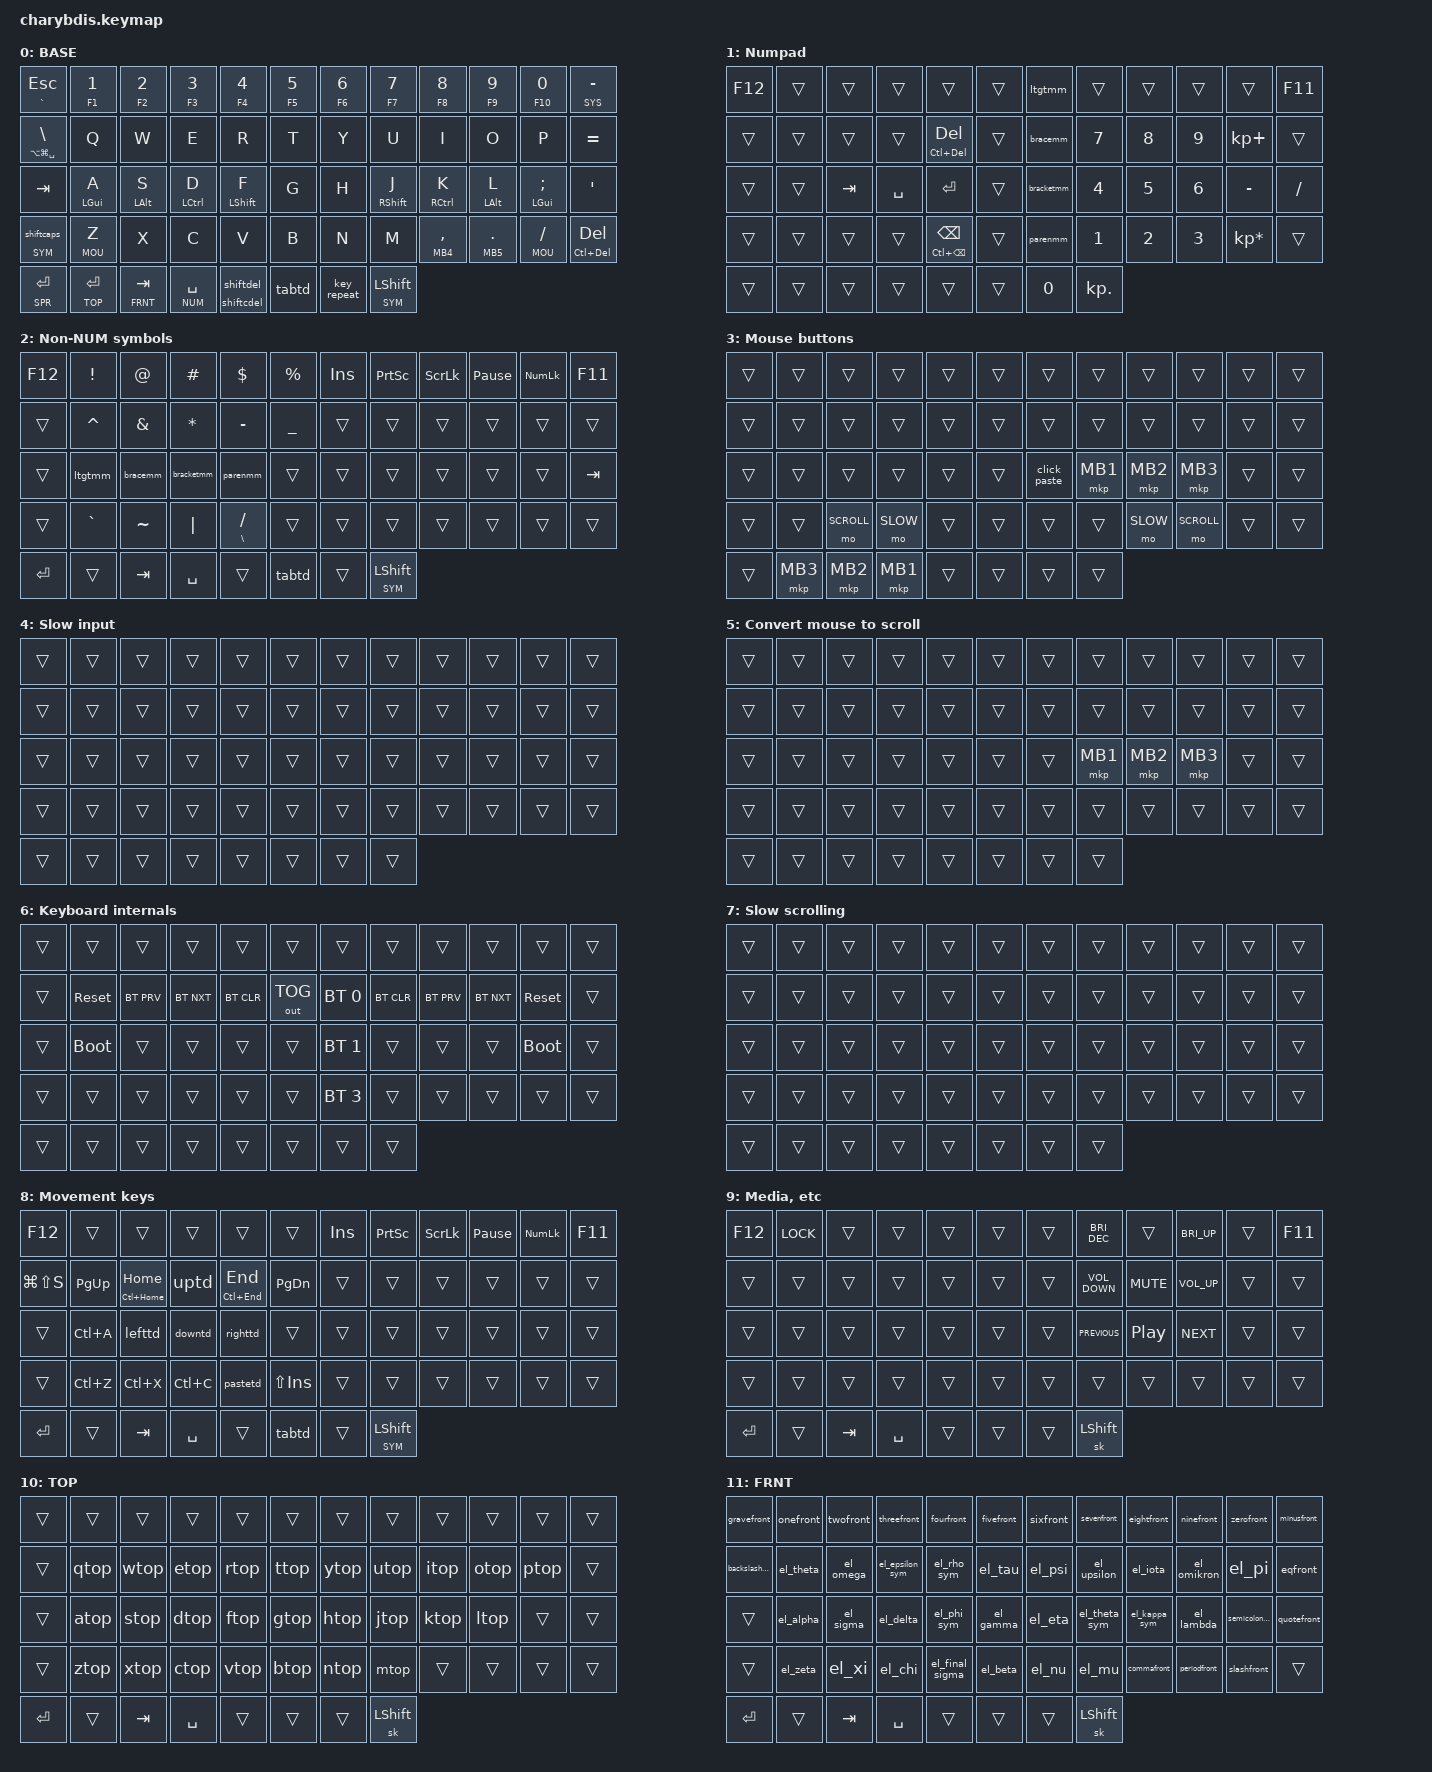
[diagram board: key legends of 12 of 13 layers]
// dt-formatter: indent="  "
#include <dt-bindings/zmk/mouse.h>
#include <behaviors/mouse_keys.dtsi>
#include <input/processors.dtsi>
#include <dt-bindings/zmk/input_transform.h>
#include <behaviors/mouse_move.dtsi>

#include <behaviors.dtsi>
#include <dt-bindings/zmk/bt.h>
#include <dt-bindings/zmk/keys.h>
#include <dt-bindings/zmk/outputs.h>
#include <dt-bindings/zmk/pointing.h>

// Can't move these into tree? Get moved by Keymap-Editor, annoyingly.
#include "zmk-helpers/helper.h" // Source after behaviors.dtsi
#include "zmk-helpers/unicode-chars/greek.dtsi" // Named Greek language characters for Front layer
#include "unicode.dtsi" // Single unicode chars for Top layer

// Utility
#define __ &trans
#define BASE 0
#define NUM 1
#define SYM 2
#define MOU 3
#define SLOW 4
#define SCROLL 5
#define SYS 6
#define SLSC 7
#define NAV 8
#define SPR 9
#define TOP 10
#define FRNT 11
#define WIN 12

// Set default row/column to actual key grid transform
/ {
  chosen { zmk,matrix_transform = &default_transform; };
};

// Default mod-tap settings
&mt {
  quick-tap-ms = <100>;
  global-quick-tap;
  flavor = "tap-preferred";
  tapping-term-ms = <170>;
};

// Default layer-tap settings
&lt {
  quick-tap-ms = <100>;
  global-quick-tap;
  flavor = "tap-preferred";
  tapping-term-ms = <170>;
};

// Defaults for caps-word behaviour
&caps_word { continue-list = <UNDERSCORE BACKSPACE DELETE MINUS>; };

// zip scaler takes mult/divisor to create multiplier. 1.5x is too fast. 1 seems fine?
&trackball_listener {
  input-processors =
    <&zip_xy_transform (INPUT_TRANSFORM_Y_INVERT | INPUT_TRANSFORM_X_INVERT | INPUT_TRANSFORM_XY_SWAP)>,
    <&zip_xy_scaler 5 4>,
    <&my_temp_layer MOU 500>;

  sniper {
    layers = <SLOW SLSC>;
    input-processors = <&zip_xy_scaler 1 8>;
    process-next;
  };

  scroller {
    layers = <SCROLL SLSC>;
    input-processors =
      <&zip_xy_transform (INPUT_TRANSFORM_X_INVERT | INPUT_TRANSFORM_XY_SWAP)>,
      <&zip_xy_to_scroll_mapper>;
  };
};

/ {
  combos {
		compatible = "zmk,combos";

		winmove {
      bindings = <&mo WIN>;
      key-positions = <55 53>;
    };
	};

  macros {
    click_paste: click_paste {
      compatible = "zmk,behavior-macro";
      #binding-cells = <0>;
      bindings
        = <&macro_tap &mkp MB1>
        , <&kp LC(V)>
        ;
    };
  };

  behaviors {
		/* Fancy alt-tab on single key. Might remove timeout to get used to interrup
			 ting with a key */
    swapper: swapper {
      compatible = "zmk,behavior-tri-state";
      #binding-cells = <0>;
      timeout-ms = <1500>; // Fire behavior x ms after release, *or* when a non-ignored key is pressed
      ignored-key-positions = <24 27 31 55 53>;

      bindings = <&kt LALT>, <&kp TAB>, <&kt LALT>;
    };

		/* Mouse buttons on hold for forward/back */
    mouse_tap: mouse_tap {
      compatible = "zmk,behavior-hold-tap";
      bindings = <&mkp>, <&kp>;

      #binding-cells = <2>;
      flavor = "tap-preferred";
      tapping-term-ms = <170>;
      quick-tap-ms = <100>;
    };

		/* Adds layer on hold to existing caps word/caps lock behaviour */
    caps_tap: caps_tap {
      compatible = "zmk,behavior-hold-tap";
      bindings = <&mo>, <&shiftcaps>;

      #binding-cells = <2>;
      tapping-term-ms = <170>;
      quick-tap-ms = <100>;
      flavor = "tap-preferred";
    };

		/* Hold-tap for backspace and delete */
		backspace_tap: backspace_tap {
      compatible = "zmk,behavior-hold-tap";
      bindings = <&shiftcdel>, <&shiftdel>;

      #binding-cells = <2>;
      tapping-term-ms = <170>;
      quick-tap-ms = <100>;
      flavor = "tap-preferred";
    };

		/* Home Row Mod behaviours */
    rhtap: rhtap {
      compatible = "zmk,behavior-hold-tap";
      bindings = <&kp>, <&kp>;

      #binding-cells = <2>;
      tapping-term-ms = <300>;
      quick-tap-ms = <175>;
			require-prior-idle-ms = <25>;
      flavor = "balanced";
      hold-trigger-key-positions = <13 25 14 26 37 38 39 15 27 16 40 28 17 29 41 5 4 3 2 1 0 24 49 52 51 12 36 50 48>;
      hold-trigger-on-release;
    };

		rhshift: rhshift {
      compatible = "zmk,behavior-hold-tap";
      bindings = <&kp>, <&kp>;

      #binding-cells = <2>;
      tapping-term-ms = <300>;
      quick-tap-ms = <175>;
			// require-prior-idle-ms = <25>; // Remove this for shift key only?
      flavor = "balanced";
      hold-trigger-key-positions = <13 25 14 26 37 38 39 15 27 16 40 28 17 29 41 5 4 3 2 1 0 24 49 52 51 12 36 50 48>;
      hold-trigger-on-release;
    };

    lhtap: lhtap {
      compatible = "zmk,behavior-hold-tap";
      bindings = <&kp>, <&kp>;

      #binding-cells = <2>;
      tapping-term-ms = <300>;
      quick-tap-ms = <175>;
			require-prior-idle-ms = <25>;
      flavor = "balanced";
      hold-trigger-key-positions = <18 22 30 31 32 33 34 42 43 44 45 46 19 20 21 22 54 10 9 8 7 6 10 11 22 23 35 47 55 53>;
      hold-trigger-on-release;
    };

		lhshift: lhshift {
      compatible = "zmk,behavior-hold-tap";
      bindings = <&kp>, <&kp>;

      #binding-cells = <2>;
      tapping-term-ms = <300>;
      quick-tap-ms = <175>;
			// require-prior-idle-ms = <25>; // Remove this for shift key only? 
      flavor = "balanced";
      hold-trigger-key-positions = <18 22 30 31 32 33 34 42 43 44 45 46 19 20 21 22 54 10 9 8 7 6 10 11 22 23 35 47 55 53>;
      hold-trigger-on-release;
    };

		/* Arrow keys - still a work in progress */
    lefttd: lefttd {
      compatible = "zmk,behavior-tap-dance";
      #binding-cells = <0>;
      bindings = <&kp LEFT_ARROW>, <&mt LC(LS(LEFT_ARROW)) LC(LEFT_ARROW)>;
    };

    righttd: righttd {
      compatible = "zmk,behavior-tap-dance";
      #binding-cells = <0>;
      bindings = <&mt LC(LS(RIGHT_ARROW)) RIGHT_ARROW>, <&kp LC(RIGHT_ARROW)>;
    };

    uptd: uptd {
      compatible = "zmk,behavior-tap-dance";
      #binding-cells = <0>;
      bindings = <&mt LC(LS(UP_ARROW)) UP_ARROW>, <&kp LC(UP_ARROW)>;
    };

    downtd: downtd {
      compatible = "zmk,behavior-tap-dance";
      #binding-cells = <0>;
      bindings = <&mt LC(LS(DOWN_ARROW)) DOWN_ARROW>, <&kp LC(DOWN_ARROW)>;
    };

		/* For nav layer; paste on single tap, windows paste on 2 taps */
    pastetd: pastetd {
      compatible = "zmk,behavior-tap-dance";
      #binding-cells = <0>;
      bindings = <&kp LC(V)>, <&kp LG(V)>;
    };

    /* Left bracket on normal press, right bracket on shift-press */
    bracketmm: bracketmm {
      compatible = "zmk,behavior-mod-morph";
      bindings = <&kp LEFT_BRACKET>, <&kp RIGHT_BRACKET>;

      #binding-cells = <0>;
      mods = <(MOD_RSFT|MOD_LSFT)>;
    };

    parenmm: parenmm {
      compatible = "zmk,behavior-mod-morph";
      bindings = <&kp LEFT_PARENTHESIS>, <&kp RIGHT_PARENTHESIS>;

      #binding-cells = <0>;
      mods = <(MOD_LSFT|MOD_RSFT)>;
    };

    bracemm: bracemm {
      compatible = "zmk,behavior-mod-morph";
      bindings = <&kp LEFT_BRACE>, <&kp RIGHT_BRACE>;

      #binding-cells = <0>;
      mods = <(MOD_LSFT|MOD_RSFT)>;
    };

    ltgtmm: ltgtmm {
      compatible = "zmk,behavior-mod-morph";
      bindings = <&kp LESS_THAN>, <&kp GREATER_THAN>;

      #binding-cells = <0>;
      mods = <(MOD_LSFT|MOD_RSFT)>;
    };

		/* Sticky shift + Layer on hold */
    stickyshift_tap: stickyshift_tap {
      compatible = "zmk,behavior-hold-tap";
      bindings = <&mo>, <&sk>;

      #binding-cells = <2>;
      tapping-term-ms = <170>;
      quick-tap-ms = <100>;
      flavor = "tap-preferred";
    };
		
		/* Existing caps word behaviour on tap + Real caps lock on Shift-tap. Can be
			 combined into a further mod-tap for layers.  */
    shiftcaps: shiftcaps {
      compatible = "zmk,behavior-mod-morph";
      bindings = <&caps_word>, <&kp CAPSLOCK>;

      #binding-cells = <0>;
      mods = <(MOD_LSFT|MOD_RSFT)>;
    };

    /* Backspace normally, delete on shift */
		shiftdel: shiftdel {
      compatible = "zmk,behavior-mod-morph";
      bindings = <&kp BACKSPACE>, <&kp DELETE>;

      #binding-cells = <0>;
      mods = <(MOD_LSFT|MOD_RSFT)>;
    };

    /* C-Backspace normally, C-delete on shift */
		shiftcdel: shiftcdel {
      compatible = "zmk,behavior-mod-morph";
      bindings = <&kp LC(BACKSPACE)>, <&kp LC(DELETE)>;

      #binding-cells = <0>;
      mods = <(MOD_LSFT|MOD_RSFT)>;
    };
		
		/* Runs swapper on hold of tab key */
    tabtap: tabtap {
      compatible = "zmk,behavior-hold-tap";
      bindings = <&swapper>, <&kp>;

      #binding-cells = <2>;
      tapping-term-ms = <170>;
      flavor = "tap-preferred";
    };

    /* Run swapper on double-tap of layer key, alt tab on single tap */
		tabtd: tabtd {
			compatible = "zmk,behavior-tap-dance";
			#binding-cells = <0>;
			bindings = <&lt NAV LA(TAB)>, <&swapper>;
 		};

		/* layertab: layertab { */
		/* 	compatible = "zmk,behavior-hold-tap"; */
		/* 	bindings = <&mo>, <&tabtd>; */
		/* 	#binding-cells = <2>; */
		/* 	tapping-term-ms = <170>; */
		/* 	flavor = "tap-preferred"; */
		/* }; */

    /* Zip-to-layer for mouse mode */
    /omit-if-no-ref/
    my_temp_layer: my_temp_layer {
      compatible = "zmk,input-processor-temp-layer";
      #input-processor-cells = <2>;
      require-prior-idle-ms = <500>;
      excluded-positions = <31 32 33 37 38 39 44 45 46>;
    };
  };

  keymap {
    compatible = "zmk,keymap";

    BASE {
      bindings = <
      // 0-11
      &mt GRAVE ESCAPE  &mt F1 NUMBER_1  &mt F2 NUMBER_2  &mt F3 NUMBER_3  &mt F4 NUMBER_4  &mt F5 NUMBER_5  &mt F6 NUMBER_6  &mt F7 NUMBER_7  &mt F8 NUMBER_8  &mt F9 NUMBER_9  &mt F10 NUMBER_0  &lt SYS MINUS
      // 12-23
      &mt LA(LG(SPACE)) BACKSLASH  &kp Q  &kp W  &kp E  &kp R  &kp T  &kp Y  &kp U  &kp I  &kp O  &kp P  &kp EQUAL
      // 24-35
      &kp TAB  &lhtap LEFT_GUI A  &lhtap LALT S  &lhtap LCTRL D  &lhshift LSHIFT F  &kp G  &kp H  &rhshift RSHIFT J  &rhtap RCTRL K  &rhtap LEFT_ALT L  &rhtap LEFT_GUI SEMI  &kp APOS
      // 36-47
      &caps_tap SYM 0  &lt MOU Z  &kp X  &kp C  &kp V  &kp B  &kp N  &kp M  &mouse_tap MB4 COMMA  &mouse_tap MB5 PERIOD  &lt MOU SLASH  &mt LC(DELETE) DELETE
      // 48-55; Physical left hand: 50, 51, 48, 52, 49; Right hand: 55, 54, 53
      &lt SPR ENTER  &lt TOP ENTER  &lt FRNT TAB  &lt NUM SPACE  &backspace_tap 0 0  &tabtd  &key_repeat  &stickyshift_tap SYM LEFT_SHIFT
      >;
    };

    NUM {
      bindings = <
      &kp F12    __  __       __         __                           __  &ltgtmm     __      __      __      __               &kp F11
      __         __  __       __         &mt LC(DEL) DELETE           __  &bracemm    &kp N7  &kp N8  &kp N9  &kp KP_PLUS      __
      __         __  &kp TAB  &kp SPACE  &kp ENTER                    __  &bracketmm  &kp N4  &kp N5  &kp N6  &kp MINUS        &kp SLASH
      __         __  __       __         &mt LC(BACKSPACE) BACKSPACE  __  &parenmm    &kp N1  &kp N2  &kp N3  &kp KP_MULTIPLY  __
      __         __  __       __         __                           __  &kp N0      &kp KP_DOT
      >;

      display-name = "Numpad";
    };

    /* Note - haven't had much use for symbol layer; just use number keys. */
    SYM {
      bindings = <
&kp F12  &kp EXCLAMATION  &kp AT_SIGN    &kp HASH      &kp DOLLAR           &kp PERCENT  &kp INSERT          &kp PRINTSCREEN  &kp SCROLLLOCK  &kp PAUSE_BREAK  &kp KP_NUMLOCK  &kp F11
__   &kp CARET        &kp AMPERSAND  &kp ASTERISK  &kp MINUS            &kp UNDER                __  __           __          __           __          __
__   &ltgtmm          &bracemm       &bracketmm    &parenmm             __                   __  __           __          __           __          &kp TAB
__   &kp GRAVE        &kp TILDE      &kp PIPE      &mt BACKSLASH SLASH  __                   __  __           __          __           __          __
         &kp ENTER        __         &kp TAB       &kp SPACE            __       &tabtd              __                           &stickyshift_tap SYM LEFT_SHIFT
      >;

      display-name = "Non-NUM symbols";
    };

    MOU {
      bindings = <
__  __  __    __    __    __  __          __    __    __    __  __
__  __  __    __    __    __          __  __    __    __    __  __
__  __  __    __    __    __         &click_paste  &mkp MB1  &mkp MB2  &mkp MB3  __  __
__  __  &mo SCROLL     &mo SLOW     __    __          __  __    &mo SLOW     &mo SCROLL     __  __
        __  &mkp MB3  &mkp MB2  &mkp MB1  __  __          __              __
      >;

      display-name = "Mouse buttons";
    };

    SLOW {
      bindings = <
      __  __  __  __  __  __  __          __  __  __  __  __
      __  __  __  __  __  __          __  __  __  __  __  __
      __  __  __  __  __  __          __  __  __  __  __  __
      __  __  __  __  __  __          __  __  __  __  __  __
      __  __  __  __  __  __          __          __
      >;

      display-name = "Slow input";
    };

    SCROLL {
      bindings = <
      __  __  __  __  __  __  __          __    __    __    __  __
      __  __  __  __  __  __          __  __    __    __    __  __
      __  __  __  __  __  __          __  &mkp MB1  &mkp MB2  &mkp MB3  __  __
      __  __  __  __  __  __          __  __    __    __    __  __
      __  __  __  __  __  __          __              __
      >;

      display-name = "Convert mouse to scroll";
    };

    SYS {
      bindings = <
      __  __       __      __      __      __        __                __      __      __      __       __
      __  &sys_reset   &bt BT_PRV  &bt BT_NXT  &bt BT_CLR  &out OUT_TOG          &bt BT_SEL 0  &bt BT_CLR  &bt BT_PRV  &bt BT_NXT  &sys_reset   __
      __  &bootloader  __      __      __      __                &bt BT_SEL 1  __      __      __      &bootloader  __
      __  __       __      __      __      __                &bt BT_SEL 3  __      __      __      __       __
      __  __  __  __  __  __  __  __
      >;

      display-name = "Keyboard internals";
    };

    SLSC {
      bindings = <
      __  __  __  __  __  __  __  __  __  __  __  __
      __  __  __  __  __  __  __  __  __  __  __  __
      __  __  __  __  __  __  __  __  __  __  __  __
      __  __  __  __  __  __  __  __  __  __  __  __
      __  __  __  __  __  __  __  __
      >;

      display-name = "Slow scrolling";
    };

    NAV {
      bindings = <
      &kp F12                  __       __             __     __           __         &kp INS          &kp PRINTSCREEN  &kp SCROLLLOCK  &kp PAUSE_BREAK  &kp KP_NUMLOCK  &kp F11
      &kp LG(LS(S))  &kp PAGE_UP  &mt LC(HOME) HOME  &uptd      &mt LC(END) END  &kp PAGE_DOWN           __  __           __          __           __          __
      __                   &kp LC(A)    &lefttd            &downtd    &righttd         __                  __  __           __          __           __          __
      __                   &kp LC(Z)    &kp LC(X)          &kp LC(C)  &pastetd         &kp LS(INS)             __  __           __          __           __          __
      &kp ENTER  __  &kp TAB  &kp SPACE  __  &tabtd  __  &stickyshift_tap SYM LEFT_SHIFT
      >;

      display-name = "Movement keys";
    };

    SPR {
      bindings = <
&kp F12  &kp K_LOCK  __  __   __     __  __          &kp C_BRIGHTNESS_DEC  __            &kp C_BRI_UP     __  &kp F11
__   __      __  __   __     __          __  &kp C_VOLUME_DOWN     &kp C_MUTE        &kp C_VOLUME_UP  __  __
__   __      __  __   __     __          __  &kp C_PREVIOUS        &kp C_PLAY_PAUSE  &kp C_NEXT       __  __
__   __      __  __   __     __          __  __                __            __           __  __
         &kp ENTER   __  &kp TAB  &kp SPACE  __  __          __                                  &sk LEFT_SHIFT
      >;

      display-name = "Media, etc";
    };

    TOP {
      bindings = <
__  __     __  __   __     __  __         __  __  __      __  __
__  &qtop      &wtop   &etop    &rtop      &ttop           &ytop  &utop   &itop   &otop       &ptop   __
__  &atop      &stop   &dtop    &ftop      &gtop           &htop  &jtop   &ktop   &ltop       __  __
__  &ztop      &xtop   &ctop    &vtop      &btop           &ntop  &mtop   __  __      __  __
        &kp ENTER  __  &kp TAB  &kp SPACE  __  __         __          &sk LSHIFT
      >;
    };

    FRNT {
      bindings = <
&gravefront      &onefront  &twofront  &threefront      &fourfront       &fivefront  &sixfront           &sevenfront    &eightfront    &ninefront      &zerofront       &minusfront
&backslashfront  &el_theta  &el_omega  &el_epsilon_sym  &el_rho_sym      &el_tau                &el_psi  &el_upsilon    &el_iota       &el_omikron     &el_pi           &eqfront
__           &el_alpha  &el_sigma  &el_delta        &el_phi_sym      &el_gamma              &el_eta  &el_theta_sym  &el_kappa_sym  &el_lambda      &semicolonfront  &quotefront
__           &el_zeta   &el_xi     &el_chi          &el_final_sigma  &el_beta               &el_nu   &el_mu         &commafront    &periodfront    &slashfront      __
                 &kp ENTER  __     &kp TAB          &kp SPACE        __      __              __                        &sk LEFT_SHIFT
      >;
    };

		WIN {
      bindings = <
&kp F12                  __       __             __     __           __         &kp INS          &kp PRINTSCREEN  &kp SCROLLLOCK  &kp PAUSE_BREAK  &kp KP_NUMLOCK  &kp F11
&kp LG(LS(S))  &kp LG(TAB)  &kp LG(LC(LEFT))  &kp LG(UP)      &kp LG(LC(RIGHT))  &kp LG(LC(D))           __  __           __          __        __         __
__                   &kp LC(A)    &kp LG(LEFT)            &kp LG(DOWN)    &kp LG(RIGHT)         &kp LG(LC(T))                  __  __           __          __           __          __
__                   &kp LC(Z)    &kp LG(LS(LEFT))          &kp LG(COMMA)  &kp LG(LS(RIGHT))         &kp LS(INS)             __  __           __          __           __          __
                         &kp ENTER    __             &kp TAB    &kp SPACE        __         __           __                           &sk LEFT_SHIFT
      >;

      display-name = "Window movement keys";
    };

  };

  conditional_layers {
    compatible = "zmk,conditional-layers";
		/* Slow scrolling */
    SnipeScroll {
      if-layers = <SLOW SCROLL>;
      then-layer = <SLSC
>;
    };

		/* Combine Sym and Nav layers for window movement */
		/* WinMove { */
		/* 	if-layers = <2 8>; */
		/* 	then-layer = <12>; */
		/* }; */
  };
};
